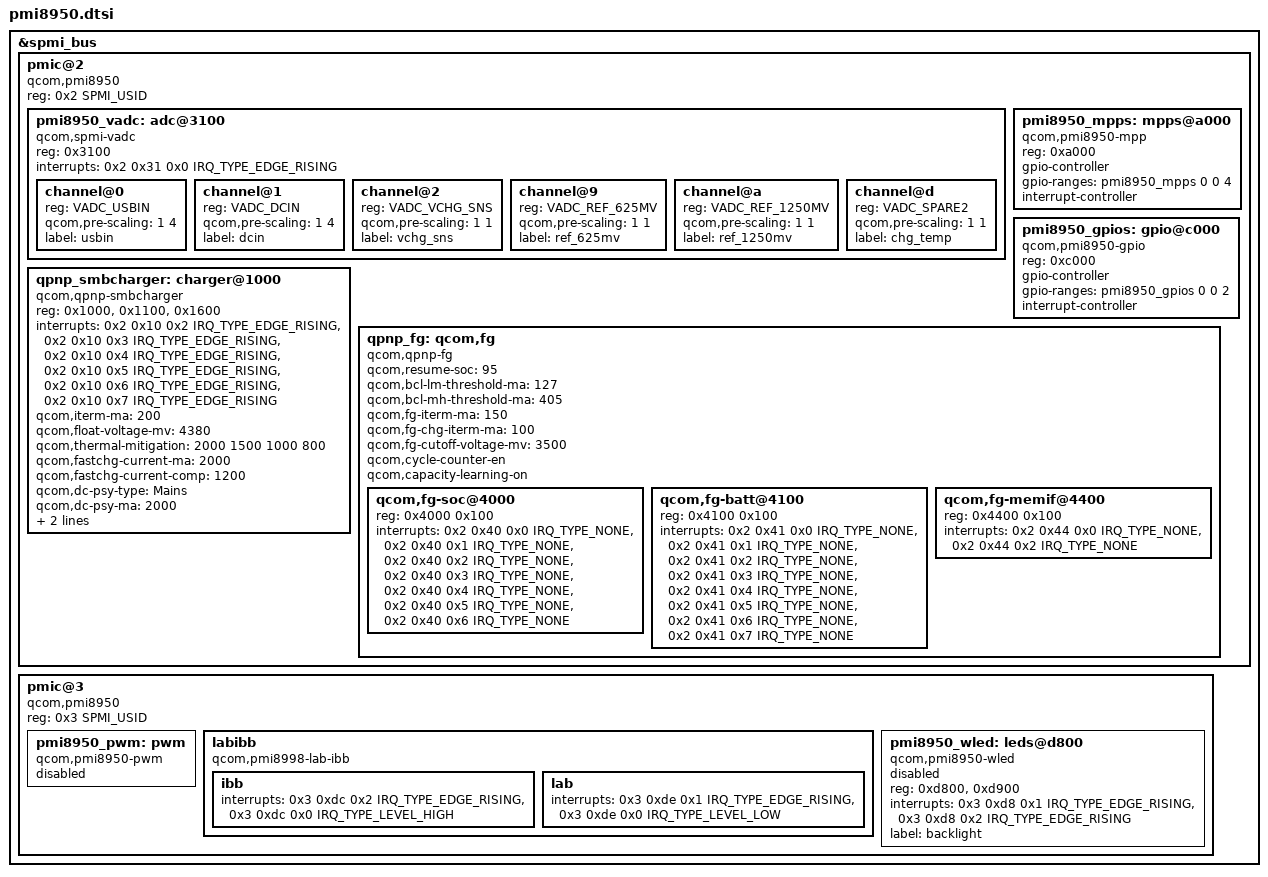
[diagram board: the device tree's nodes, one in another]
// SPDX-License-Identifier: GPL-2.0
// Copyright (c) 2019, AngeloGioacchino Del Regno <kholk11@gmail.com>

#include <dt-bindings/iio/qcom,spmi-vadc.h>
#include <dt-bindings/interrupt-controller/irq.h>
#include <dt-bindings/spmi/spmi.h>

&spmi_bus {
	pmic@2 {
		compatible = "qcom,pmi8950", "qcom,spmi-pmic";
		reg = <0x2 SPMI_USID>;
		#address-cells = <1>;
		#size-cells = <0>;

		pmi8950_vadc: adc@3100 {
			compatible = "qcom,spmi-vadc";
			reg = <0x3100>;
			interrupts = <0x2 0x31 0x0 IRQ_TYPE_EDGE_RISING>;
			#address-cells = <1>;
			#size-cells = <0>;
			#io-channel-cells = <1>;

			channel@0 {
				reg = <VADC_USBIN>;
				qcom,pre-scaling = <1 4>;
				label = "usbin";
			};

			channel@1 {
				reg = <VADC_DCIN>;
				qcom,pre-scaling = <1 4>;
				label = "dcin";
			};

			channel@2 {
				reg = <VADC_VCHG_SNS>;
				qcom,pre-scaling = <1 1>;
				label = "vchg_sns";
			};

			channel@9 {
				reg = <VADC_REF_625MV>;
				qcom,pre-scaling = <1 1>;
				label = "ref_625mv";
			};

			channel@a {
				reg = <VADC_REF_1250MV>;
				qcom,pre-scaling = <1 1>;
				label = "ref_1250mv";
			};

			channel@d {
				reg = <VADC_SPARE2>;
				qcom,pre-scaling = <1 1>;
				label = "chg_temp";
			};
		};

		pmi8950_mpps: mpps@a000 {
			compatible = "qcom,pmi8950-mpp", "qcom,spmi-mpp";
			reg = <0xa000>;
			gpio-controller;
			gpio-ranges = <&pmi8950_mpps 0 0 4>;
			#gpio-cells = <2>;
			interrupt-controller;
			#interrupt-cells = <2>;
		};

		pmi8950_gpios: gpio@c000 {
			compatible = "qcom,pmi8950-gpio", "qcom,spmi-gpio";
			reg = <0xc000>;
			gpio-controller;
			gpio-ranges = <&pmi8950_gpios 0 0 2>;
			#gpio-cells = <2>;
			interrupt-controller;
			#interrupt-cells = <2>;
		};

		/*
		 * PMI8950 充电器 / 电量计 —— 从下游 4.19 移植的 QPNP 驱动。
		 *
		 * 参数取自 4.19 的 oppo-msm8953/pmi8950.dtsi（R9s 用的是
		 * PMI8950 的 SMB 充电器 + FG 电量计，不是 smb2/smb5 那一代）。
		 *
		 * 注意 6.12 的 power_supply 框架里 qcom,vchg_sns-vadc 这种
		 * 私有 ADC phandle 已经改成标准 IIO consumer（iio_channel_get），
		 * 所以这里用 io-channels / io-channel-names 表达。
		 */
		qpnp_smbcharger: charger@1000 {
			compatible = "qcom,qpnp-smbcharger";
			reg = <0x1000>, <0x1100>, <0x1600>;

			interrupts = <0x2 0x10 0x2 IRQ_TYPE_EDGE_RISING>,
				     <0x2 0x10 0x3 IRQ_TYPE_EDGE_RISING>,
				     <0x2 0x10 0x4 IRQ_TYPE_EDGE_RISING>,
				     <0x2 0x10 0x5 IRQ_TYPE_EDGE_RISING>,
				     <0x2 0x10 0x6 IRQ_TYPE_EDGE_RISING>,
				     <0x2 0x10 0x7 IRQ_TYPE_EDGE_RISING>;
			interrupt-names = "chg-done", "chg-false-done",
					  "batt-hot", "chg-trim-done",
					  "batt-trim-done", "chg-trim-delta";

			qcom,iterm-ma = <200>;
			qcom,float-voltage-mv = <4380>;
			qcom,thermal-mitigation = <2000 1500 1000 800>;
			qcom,fastchg-current-ma = <2000>;
			qcom,fastchg-current-comp = <1200>;
			qcom,dc-psy-type = "Mains";
			qcom,dc-psy-ma = <2000>;
			qcom,hvdcp-not-supported;

			io-channels = <&pmi8950_vadc 3>;
			io-channel-names = "vchg_sns";

			status = "okay";
		};

		/*
		 * QPNP 电量计。结构必须按 4.19 vendor 的层级来：
		 * qpnp-fg 驱动在 fg_init_irqs() 里先 of_get_available_child_count()
		 * 检查子节点（为 0 直接 -ENXIO），再用 for_each_available_child_of_node
		 * + of_irq_get_byname 从每个子节点按名字取中断。
		 * 所以不能写成平铺的 interrupts，必须有三个子节点。
		 */
		qpnp_fg: qcom,fg {
			compatible = "qcom,qpnp-fg";
			#address-cells = <1>;
			#size-cells = <1>;

			qcom,resume-soc = <95>;
			qcom,bcl-lm-threshold-ma = <127>;
			qcom,bcl-mh-threshold-ma = <405>;
			qcom,fg-iterm-ma = <150>;
			qcom,fg-chg-iterm-ma = <100>;
			qcom,fg-cutoff-voltage-mv = <3500>;
			qcom,cycle-counter-en;
			qcom,capacity-learning-on;

			qcom,fg-soc@4000 {
				status = "okay";
				reg = <0x4000 0x100>;
				interrupts = <0x2 0x40 0x0 IRQ_TYPE_NONE>,
					     <0x2 0x40 0x1 IRQ_TYPE_NONE>,
					     <0x2 0x40 0x2 IRQ_TYPE_NONE>,
					     <0x2 0x40 0x3 IRQ_TYPE_NONE>,
					     <0x2 0x40 0x4 IRQ_TYPE_NONE>,
					     <0x2 0x40 0x5 IRQ_TYPE_NONE>,
					     <0x2 0x40 0x6 IRQ_TYPE_NONE>;
				interrupt-names = "high-soc", "low-soc", "full-soc",
						  "empty-soc", "delta-soc",
						  "first-est-done", "update-soc";
			};

			qcom,fg-batt@4100 {
				reg = <0x4100 0x100>;
				interrupts = <0x2 0x41 0x0 IRQ_TYPE_NONE>,
					     <0x2 0x41 0x1 IRQ_TYPE_NONE>,
					     <0x2 0x41 0x2 IRQ_TYPE_NONE>,
					     <0x2 0x41 0x3 IRQ_TYPE_NONE>,
					     <0x2 0x41 0x4 IRQ_TYPE_NONE>,
					     <0x2 0x41 0x5 IRQ_TYPE_NONE>,
					     <0x2 0x41 0x6 IRQ_TYPE_NONE>,
					     <0x2 0x41 0x7 IRQ_TYPE_NONE>;
				interrupt-names = "soft-cold", "soft-hot", "vbatt-low",
						  "batt-ided", "batt-id-req",
						  "batt-unknown", "batt-missing",
						  "batt-match";
			};

			qcom,fg-memif@4400 {
				status = "okay";
				reg = <0x4400 0x100>;
				interrupts = <0x2 0x44 0x0 IRQ_TYPE_NONE>,
					     <0x2 0x44 0x2 IRQ_TYPE_NONE>;
				interrupt-names = "mem-avail", "data-rcvry-sug";
			};
		};

	};

	pmic@3 {
		compatible = "qcom,pmi8950", "qcom,spmi-pmic";
		reg = <0x3 SPMI_USID>;
		#address-cells = <1>;
		#size-cells = <0>;

		pmi8950_pwm: pwm {
			compatible = "qcom,pmi8950-pwm";
			#pwm-cells = <2>;

			status = "disabled";
		};

		/*
		 * LCD bias（LAB/IBB）—— OPPO R9s 的 16027(JDI) / 16017(Samsung)
		 * 面板都要这个正负压轨。
		 *
		 * 用主线驱动的 compatible（qcom,pmi8998-lab-ibb），因为：
		 *   · 4.9/4.19 用的是私有驱动 qcom,qpnp-labibb-regulator，
		 *     主线没有这个 driver；
		 *   · 主线 qcom-labibb-regulator.c 里 LAB/IBB 的寄存器基址
		 *     硬编码为 0xde00/0xdc00，与 PMI8950 的 lab@de00 / ibb@dc00
		 *     完全一致（见 4.9 下游 pmi8950.dtsi），所以可以直接复用；
		 *   · labibb 挂在 PMI8950 的 SPMI USID 3 上，与 pmi8998 相同。
		 */
		labibb {
			compatible = "qcom,pmi8998-lab-ibb";

			ibb: ibb {
				interrupts = <0x3 0xdc 0x2 IRQ_TYPE_EDGE_RISING>,
					     <0x3 0xdc 0x0 IRQ_TYPE_LEVEL_HIGH>;
				interrupt-names = "sc-err", "ocp";
			};

			lab: lab {
				interrupts = <0x3 0xde 0x1 IRQ_TYPE_EDGE_RISING>,
					     <0x3 0xde 0x0 IRQ_TYPE_LEVEL_LOW>;
				interrupt-names = "sc-err", "ocp";
			};
		};

		pmi8950_wled: leds@d800 {
			compatible = "qcom,pmi8950-wled";
			reg = <0xd800>, <0xd900>;
			interrupts = <0x3 0xd8 0x1 IRQ_TYPE_EDGE_RISING>,
				     <0x3 0xd8 0x2 IRQ_TYPE_EDGE_RISING>;
			interrupt-names = "ovp", "short";
			label = "backlight";

			status = "disabled";
		};
	};
};
